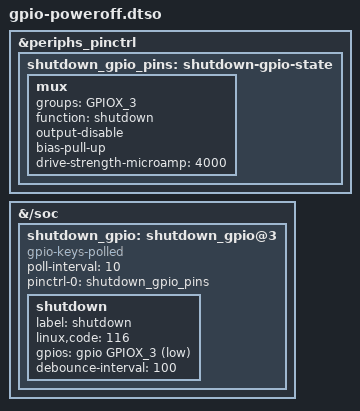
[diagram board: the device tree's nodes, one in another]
/dts-v1/;
/plugin/;

#include <dt-bindings/gpio/meson-g12a-gpio.h>
#include <dt-bindings/gpio/gpio.h>

/ {
	fragment@0 {
		target = <&periphs_pinctrl>;

		__overlay__ {
			shutdown_gpio_pins: shutdown-gpio-state {
				mux {
					groups = "GPIOX_3";
					function = "shutdown";
					output-disable;
					bias-pull-up;
					drive-strength-microamp = <4000>;
				};
			};
		};
	};

	fragment@1 {
		target-path = "/soc";

		__overlay__ {
			shutdown_gpio: shutdown_gpio@3 {
				compatible = "gpio-keys-polled";
				poll-interval = <10>;
				pinctrl-names = "default";
				pinctrl-0 = <&shutdown_gpio_pins>;

				status = "okay";

				shutdown {
					label = "shutdown";
					linux,code = <116>;
					gpios = <&gpio GPIOX_3 GPIO_ACTIVE_LOW>;
					debounce-interval = <100>;
				};
			};
		};
	};
};
